[part 22 of 23: package /ComponentTypes]
AUTOSAR XML (schema 4-3-0)
package /ComponentTypes  (continued)
  composition sw component type Geltungsbereich_E3_1_1_UNECE_Gen2  (continued)
    delegate Grundumfang_XIX_Klima.SP_IF_Thermo_Pred_Innen_System_Anf_XIX_Grundumfang_XIX_Klima <-> outer port SP_IF_Thermo_Pred_Innen_System_Anf_XIX_Klima
    delegate Grundumfang_XIX_Klima.SP_IF_Thermo_Pred_P_dyn_In_Efficien1_XIX_Grundumfang_XIX_Klima <-> outer port SP_IF_Thermo_Pred_P_dyn_In_Efficien1_XIX_Klima
    delegate Grundumfang_XIX_Klima.SP_IF_Thermo_Pred_P_dyn_In_Efficien2_XIX_Grundumfang_XIX_Klima <-> outer port SP_IF_Thermo_Pred_P_dyn_In_Efficien2_XIX_Klima
    delegate Grundumfang_XIX_Klima.SP_IF_Thermo_Pred_P_dyn_In_Standard_XIX_Grundumfang_XIX_Klima <-> outer port SP_IF_Thermo_Pred_P_dyn_In_Standard_XIX_Klima
    delegate Grundumfang_XIX_Klima.SP_IF_Thermo_Pred_P_dyn_Innen_XIX_Grundumfang_XIX_Klima <-> outer port SP_IF_Thermo_Pred_P_dyn_Innen_XIX_Klima
    delegate Grundumfang_XIX_Klima.SP_IF_Thermo_Pred_P_stat_In_Efficien1_XIX_Grundumfang_XIX_Klima <-> outer port SP_IF_Thermo_Pred_P_stat_In_Efficien1_XIX_Klima
    delegate Grundumfang_XIX_Klima.SP_IF_Thermo_Pred_P_stat_In_Efficien2_XIX_Grundumfang_XIX_Klima <-> outer port SP_IF_Thermo_Pred_P_stat_In_Efficien2_XIX_Klima
    delegate Grundumfang_XIX_Klima.SP_IF_Thermo_Pred_P_stat_In_Standard_XIX_Grundumfang_XIX_Klima <-> outer port SP_IF_Thermo_Pred_P_stat_In_Standard_XIX_Klima
    delegate Grundumfang_XIX_Klima.SP_IF_Thermo_Pred_P_stat_Innen_XIX_Grundumfang_XIX_Klima <-> outer port SP_IF_Thermo_Pred_P_stat_Innen_XIX_Klima
    delegate Grundumfang_XIX_Klima.SP_IF_Thermo_Pred_T_dyn_In_Efficien1_XIX_Grundumfang_XIX_Klima <-> outer port SP_IF_Thermo_Pred_T_dyn_In_Efficien1_XIX_Klima
    delegate Grundumfang_XIX_Klima.SP_IF_Thermo_Pred_T_dyn_In_Efficien2_XIX_Grundumfang_XIX_Klima <-> outer port SP_IF_Thermo_Pred_T_dyn_In_Efficien2_XIX_Klima
    delegate Grundumfang_XIX_Klima.SP_IF_Thermo_Pred_T_dyn_In_Standard_XIX_Grundumfang_XIX_Klima <-> outer port SP_IF_Thermo_Pred_T_dyn_In_Standard_XIX_Klima
    delegate Grundumfang_XIX_Klima.SP_IF_Thermo_Pred_T_dyn_Innen_XIX_Grundumfang_XIX_Klima <-> outer port SP_IF_Thermo_Pred_T_dyn_Innen_XIX_Klima
    delegate Grundumfang_XIX_Klima.SP_IF_Thermo_Verbrauch_BTL_Ueberlauf_XIX_Grundumfang_XIX_Klima <-> outer port SP_IF_Thermo_Verbrauch_BTL_Ueberlauf_XIX_Klima
    delegate Grundumfang_XIX_Klima.SP_IF_Thermo_Verbrauch_BTL_XIX_Grundumfang_XIX_Klima <-> outer port SP_IF_Thermo_Verbrauch_BTL_XIX_Klima
    delegate Grundumfang_XIX_Klima.SP_IF_Thermo_Verbrauch_Innen_Ueberlauf_XIX_Grundumfang_XIX_Klima <-> outer port SP_IF_Thermo_Verbrauch_Innen_Ueberlauf_XIX_Klima
    delegate Grundumfang_XIX_Klima.SP_IF_Thermo_Verbrauch_Innen_XIX_Grundumfang_XIX_Klima <-> outer port SP_IF_Thermo_Verbrauch_Innen_XIX_Klima
    delegate Grundumfang_XIX_Klima.SP_IF_UH_Jahr_XIX_Grundumfang_XIX_Klima <-> outer port SP_IF_UH_Jahr_XIX_Klima
    delegate Grundumfang_XIX_Klima.SP_IF_UH_Monat_XIX_Grundumfang_XIX_Klima <-> outer port SP_IF_UH_Monat_XIX_Klima
    delegate Grundumfang_XIX_Klima.SP_IF_UH_Tag_XIX_Grundumfang_XIX_Klima <-> outer port SP_IF_UH_Tag_XIX_Klima
    delegate Grundumfang_XIX_Klima.SP_IF_Umluft_XIX_Grundumfang_XIX_Klima <-> outer port SP_IF_Umluft_XIX_Klima
    delegate Grundumfang_XIX_Klima.SP_IF_Verbauposition_LLR_li_XIX_Grundumfang_XIX_Klima <-> outer port SP_IF_Verbauposition_LLR_li_XIX_Klima
    delegate Grundumfang_XIX_Klima.SP_IF_Verbauposition_LLR_re_XIX_Grundumfang_XIX_Klima <-> outer port SP_IF_Verbauposition_LLR_re_XIX_Klima
    delegate Grundumfang_XIX_Klima.SP_IF_ZAS_Kl_15_XIX_Grundumfang_XIX_Klima <-> outer port SP_IF_ZAS_Kl_15_XIX_Klima
    delegate Grundumfang_XIX_Klima.SP_IF_ZAS_Kl_S_XIX_Grundumfang_XIX_Klima <-> outer port SP_IF_ZAS_Kl_S_XIX_Klima
    connect Grundumfang_XIX_Klima.SP_IF_KL_Heizen_Status_XIX_Grundumfang_XIX_Klima -> HVEM_Auto_NL_XIX_Klima.RP_IF_KL_Heizen_Status_XIX_HVEM_Auto_NL_XIX_Klima
    connect Grundumfang_XIX_Klima.SP_IF_KL_Kuehlungs_Status_XIX_Grundumfang_XIX_Klima -> HVEM_Auto_NL_XIX_Klima.RP_IF_KL_Kuehlungs_Status_XIX_HVEM_Auto_NL_XIX_Klima
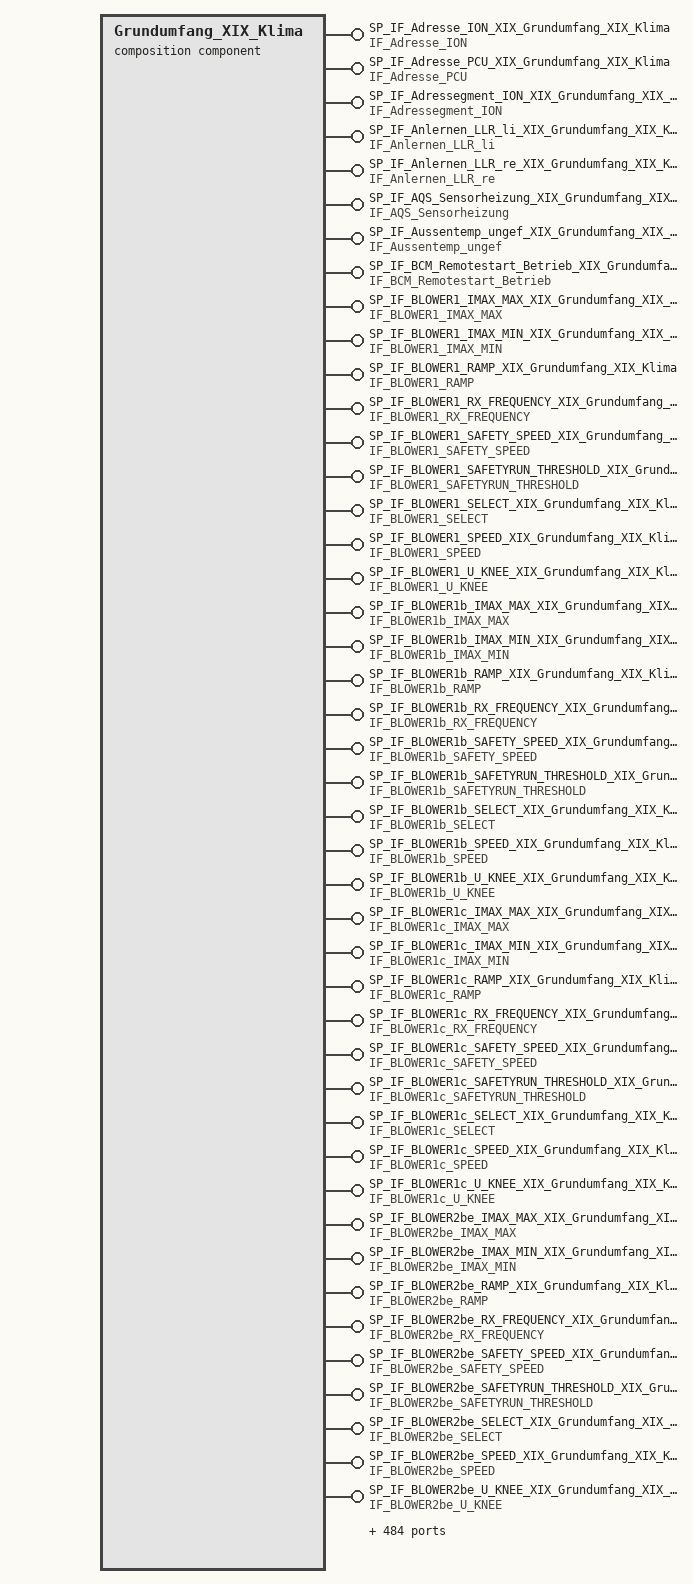
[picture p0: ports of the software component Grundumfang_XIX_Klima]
  composition sw component type Grundumfang_XIX_Klima
    543 x provide port:
      SP_IF_Adresse_ION_XIX_Grundumfang_XIX_Klima: provided-interface=IF_Adresse_ION
      SP_IF_Adresse_PCU_XIX_Grundumfang_XIX_Klima: provided-interface=IF_Adresse_PCU
      SP_IF_Adressegment_ION_XIX_Grundumfang_XIX_Klima: provided-interface=IF_Adressegment_ION
      SP_IF_Anlernen_LLR_li_XIX_Grundumfang_XIX_Klima: provided-interface=IF_Anlernen_LLR_li
      SP_IF_Anlernen_LLR_re_XIX_Grundumfang_XIX_Klima: provided-interface=IF_Anlernen_LLR_re
      SP_IF_AQS_Sensorheizung_XIX_Grundumfang_XIX_Klima: provided-interface=IF_AQS_Sensorheizung
      SP_IF_Aussentemp_ungef_XIX_Grundumfang_XIX_Klima: provided-interface=IF_Aussentemp_ungef
      SP_IF_BCM_Remotestart_Betrieb_XIX_Grundumfang_XIX_Klima: provided-interface=IF_BCM_Remotestart_Betrieb
      SP_IF_BLOWER1_IMAX_MAX_XIX_Grundumfang_XIX_Klima: provided-interface=IF_BLOWER1_IMAX_MAX
      SP_IF_BLOWER1_IMAX_MIN_XIX_Grundumfang_XIX_Klima: provided-interface=IF_BLOWER1_IMAX_MIN
      SP_IF_BLOWER1_RAMP_XIX_Grundumfang_XIX_Klima: provided-interface=IF_BLOWER1_RAMP
      SP_IF_BLOWER1_RX_FREQUENCY_XIX_Grundumfang_XIX_Klima: provided-interface=IF_BLOWER1_RX_FREQUENCY
      SP_IF_BLOWER1_SAFETY_SPEED_XIX_Grundumfang_XIX_Klima: provided-interface=IF_BLOWER1_SAFETY_SPEED
      SP_IF_BLOWER1_SAFETYRUN_THRESHOLD_XIX_Grundumfang_XIX_Klima: provided-interface=IF_BLOWER1_SAFETYRUN_THRESHOLD
      SP_IF_BLOWER1_SELECT_XIX_Grundumfang_XIX_Klima: provided-interface=IF_BLOWER1_SELECT
      SP_IF_BLOWER1_SPEED_XIX_Grundumfang_XIX_Klima: provided-interface=IF_BLOWER1_SPEED
      SP_IF_BLOWER1_U_KNEE_XIX_Grundumfang_XIX_Klima: provided-interface=IF_BLOWER1_U_KNEE
      SP_IF_BLOWER1b_IMAX_MAX_XIX_Grundumfang_XIX_Klima: provided-interface=IF_BLOWER1b_IMAX_MAX
      SP_IF_BLOWER1b_IMAX_MIN_XIX_Grundumfang_XIX_Klima: provided-interface=IF_BLOWER1b_IMAX_MIN
      SP_IF_BLOWER1b_RAMP_XIX_Grundumfang_XIX_Klima: provided-interface=IF_BLOWER1b_RAMP
      SP_IF_BLOWER1b_RX_FREQUENCY_XIX_Grundumfang_XIX_Klima: provided-interface=IF_BLOWER1b_RX_FREQUENCY
      SP_IF_BLOWER1b_SAFETY_SPEED_XIX_Grundumfang_XIX_Klima: provided-interface=IF_BLOWER1b_SAFETY_SPEED
      SP_IF_BLOWER1b_SAFETYRUN_THRESHOLD_XIX_Grundumfang_XIX_Klima: provided-interface=IF_BLOWER1b_SAFETYRUN_THRESHOLD
      SP_IF_BLOWER1b_SELECT_XIX_Grundumfang_XIX_Klima: provided-interface=IF_BLOWER1b_SELECT
      SP_IF_BLOWER1b_SPEED_XIX_Grundumfang_XIX_Klima: provided-interface=IF_BLOWER1b_SPEED
      SP_IF_BLOWER1b_U_KNEE_XIX_Grundumfang_XIX_Klima: provided-interface=IF_BLOWER1b_U_KNEE
      SP_IF_BLOWER1c_IMAX_MAX_XIX_Grundumfang_XIX_Klima: provided-interface=IF_BLOWER1c_IMAX_MAX
      SP_IF_BLOWER1c_IMAX_MIN_XIX_Grundumfang_XIX_Klima: provided-interface=IF_BLOWER1c_IMAX_MIN
      SP_IF_BLOWER1c_RAMP_XIX_Grundumfang_XIX_Klima: provided-interface=IF_BLOWER1c_RAMP
      SP_IF_BLOWER1c_RX_FREQUENCY_XIX_Grundumfang_XIX_Klima: provided-interface=IF_BLOWER1c_RX_FREQUENCY
      SP_IF_BLOWER1c_SAFETY_SPEED_XIX_Grundumfang_XIX_Klima: provided-interface=IF_BLOWER1c_SAFETY_SPEED
      SP_IF_BLOWER1c_SAFETYRUN_THRESHOLD_XIX_Grundumfang_XIX_Klima: provided-interface=IF_BLOWER1c_SAFETYRUN_THRESHOLD
      SP_IF_BLOWER1c_SELECT_XIX_Grundumfang_XIX_Klima: provided-interface=IF_BLOWER1c_SELECT
      SP_IF_BLOWER1c_SPEED_XIX_Grundumfang_XIX_Klima: provided-interface=IF_BLOWER1c_SPEED
      SP_IF_BLOWER1c_U_KNEE_XIX_Grundumfang_XIX_Klima: provided-interface=IF_BLOWER1c_U_KNEE
      SP_IF_BLOWER2be_IMAX_MAX_XIX_Grundumfang_XIX_Klima: provided-interface=IF_BLOWER2be_IMAX_MAX
      SP_IF_BLOWER2be_IMAX_MIN_XIX_Grundumfang_XIX_Klima: provided-interface=IF_BLOWER2be_IMAX_MIN
      SP_IF_BLOWER2be_RAMP_XIX_Grundumfang_XIX_Klima: provided-interface=IF_BLOWER2be_RAMP
      SP_IF_BLOWER2be_RX_FREQUENCY_XIX_Grundumfang_XIX_Klima: provided-interface=IF_BLOWER2be_RX_FREQUENCY
      SP_IF_BLOWER2be_SAFETY_SPEED_XIX_Grundumfang_XIX_Klima: provided-interface=IF_BLOWER2be_SAFETY_SPEED
      SP_IF_BLOWER2be_SAFETYRUN_THRESHOLD_XIX_Grundumfang_XIX_Klima: provided-interface=IF_BLOWER2be_SAFETYRUN_THRESHOLD
      SP_IF_BLOWER2be_SELECT_XIX_Grundumfang_XIX_Klima: provided-interface=IF_BLOWER2be_SELECT
      SP_IF_BLOWER2be_SPEED_XIX_Grundumfang_XIX_Klima: provided-interface=IF_BLOWER2be_SPEED
      SP_IF_BLOWER2be_U_KNEE_XIX_Grundumfang_XIX_Klima: provided-interface=IF_BLOWER2be_U_KNEE
      SP_IF_BLOWER2e_IMAX_MAX_XIX_Grundumfang_XIX_Klima: provided-interface=IF_BLOWER2e_IMAX_MAX
      SP_IF_BLOWER2e_IMAX_MIN_XIX_Grundumfang_XIX_Klima: provided-interface=IF_BLOWER2e_IMAX_MIN
      SP_IF_BLOWER2e_RAMP_XIX_Grundumfang_XIX_Klima: provided-interface=IF_BLOWER2e_RAMP
      SP_IF_BLOWER2e_RX_FREQUENCY_XIX_Grundumfang_XIX_Klima: provided-interface=IF_BLOWER2e_RX_FREQUENCY
      SP_IF_BLOWER2e_SAFETY_SPEED_XIX_Grundumfang_XIX_Klima: provided-interface=IF_BLOWER2e_SAFETY_SPEED
      SP_IF_BLOWER2e_SAFETYRUN_THRESHOLD_XIX_Grundumfang_XIX_Klima: provided-interface=IF_BLOWER2e_SAFETYRUN_THRESHOLD
      SP_IF_BLOWER2e_SELECT_XIX_Grundumfang_XIX_Klima: provided-interface=IF_BLOWER2e_SELECT
      SP_IF_BLOWER2e_SPEED_XIX_Grundumfang_XIX_Klima: provided-interface=IF_BLOWER2e_SPEED
      SP_IF_BLOWER2e_U_KNEE_XIX_Grundumfang_XIX_Klima: provided-interface=IF_BLOWER2e_U_KNEE
      SP_IF_BT_FH_Oeffnung_4Bit_XIX_Grundumfang_XIX_Klima: provided-interface=IF_BT_FH_Oeffnung_4Bit
      SP_IF_DI_KL_58xd_XIX_Grundumfang_XIX_Klima: provided-interface=IF_DI_KL_58xd
      SP_IF_DI_KL_58xs_XIX_Grundumfang_XIX_Klima: provided-interface=IF_DI_KL_58xs
      SP_IF_DS_Kaeltemittel_P_WP_XIX_Grundumfang_XIX_Klima: provided-interface=IF_DS_Kaeltemittel_P_WP
      SP_IF_DS_Kaeltemittel_P_XIX_Grundumfang_XIX_Klima: provided-interface=IF_DS_Kaeltemittel_P
      SP_IF_DS_Status_XIX_Grundumfang_XIX_Klima: provided-interface=IF_DS_Status
      SP_IF_EKK_Active_Discharge_XIX_Grundumfang_XIX_Klima: provided-interface=IF_EKK_Active_Discharge
      SP_IF_EKK_ENB_COMP_XIX_Grundumfang_XIX_Klima: provided-interface=IF_EKK_ENB_COMP
      SP_IF_EKK_HV_ST_XIX_Grundumfang_XIX_Klima: provided-interface=IF_EKK_HV_ST
      SP_IF_EKK_KL_15_Status_XIX_Grundumfang_XIX_Klima: provided-interface=IF_EKK_KL_15_Status
      SP_IF_EKK_REQ_COMP_SPEED_HiRes_XIX_Grundumfang_XIX_Klima: provided-interface=IF_EKK_REQ_COMP_SPEED_HiRes
      SP_IF_EKK_REQ_COMP_SPEED_XIX_Grundumfang_XIX_Klima: provided-interface=IF_EKK_REQ_COMP_SPEED
      SP_IF_EKKe_Error_Mask_Nr_XIX_Grundumfang_XIX_Klima: provided-interface=IF_EKKe_Error_Mask_Nr
      SP_IF_EKKe_Level_REQ_XIX_Grundumfang_XIX_Klima: provided-interface=IF_EKKe_Level_REQ
      SP_IF_EKKe_Q_Mask_XIX_Grundumfang_XIX_Klima: provided-interface=IF_EKKe_Q_Mask
      SP_IF_Empfindlichkeit_AQS_XIX_Grundumfang_XIX_Klima: provided-interface=IF_Empfindlichkeit_AQS
      SP_IF_ESP_v_Signal_8Bit_XIX_Grundumfang_XIX_Klima: provided-interface=IF_ESP_v_Signal_8Bit
      SP_IF_FCM_01_alt_XIX_Grundumfang_XIX_Klima: provided-interface=IF_FCM_01_alt
      SP_IF_FRS_ChannelSelect_XIX_Grundumfang_XIX_Klima: provided-interface=IF_FRS_ChannelSelect
      SP_IF_FRS_IntensityReq_XIX_Grundumfang_XIX_Klima: provided-interface=IF_FRS_IntensityReq
      SP_IF_FRS_Status_Car_XIX_Grundumfang_XIX_Klima: provided-interface=IF_FRS_Status_Car
      SP_IF_FSA_Luftfeuchte_rel_XIX_Grundumfang_XIX_Klima: provided-interface=IF_FSA_Luftfeuchte_rel
      SP_IF_FSA_Taupunkt_PMS_XIX_Grundumfang_XIX_Klima: provided-interface=IF_FSA_Taupunkt_PMS
      SP_IF_FSH_Status_XIX_Grundumfang_XIX_Klima: provided-interface=IF_FSH_Status
      SP_IF_FSH_Taster_XIX_Grundumfang_XIX_Klima: provided-interface=IF_FSH_Taster
      SP_IF_FT_FH_Oeffnung_4Bit_XIX_Grundumfang_XIX_Klima: provided-interface=IF_FT_FH_Oeffnung_4Bit
      SP_IF_Geblaesestufe_XIX_Grundumfang_XIX_Klima: provided-interface=IF_Geblaesestufe
      SP_IF_HBFS_FH_Oeffnung_4Bit_XIX_Grundumfang_XIX_Klima: provided-interface=IF_HBFS_FH_Oeffnung_4Bit
      SP_IF_HFS_FH_Oeffnung_4Bit_XIX_Grundumfang_XIX_Klima: provided-interface=IF_HFS_FH_Oeffnung_4Bit
      SP_IF_HLR_SIH_Freigabe_Fond_XIX_Grundumfang_XIX_Klima: provided-interface=IF_HLR_SIH_Freigabe_Fond
      SP_IF_HSH_Relais_Anf_XIX_Grundumfang_XIX_Klima: provided-interface=IF_HSH_Relais_Anf
      SP_IF_HSH_Taster_XIX_Grundumfang_XIX_Klima: provided-interface=IF_HSH_Taster
      SP_IF_HV_H3be_Geblaesedrehzahl_XIX_Grundumfang_XIX_Klima: provided-interface=IF_HV_H3be_Geblaesedrehzahl
      SP_IF_HV_H3be_Heizer_ein_XIX_Grundumfang_XIX_Klima: provided-interface=IF_HV_H3be_Heizer_ein
      SP_IF_HV_H3be_Heizer_links_soll_XIX_Grundumfang_XIX_Klima: provided-interface=IF_HV_H3be_Heizer_links_soll
      SP_IF_HV_H3be_Heizer_Mitte_soll_XIX_Grundumfang_XIX_Klima: provided-interface=IF_HV_H3be_Heizer_Mitte_soll
      SP_IF_HV_H3be_Heizer_rechts_soll_XIX_Grundumfang_XIX_Klima: provided-interface=IF_HV_H3be_Heizer_rechts_soll
      SP_IF_HV_H3be_Heizgaskuehler_XIX_Grundumfang_XIX_Klima: provided-interface=IF_HV_H3be_Heizgaskuehler
      SP_IF_HV_H3be_Heizsystem_XIX_Grundumfang_XIX_Klima: provided-interface=IF_HV_H3be_Heizsystem
      SP_IF_HV_H3be_PTC_Zonenanzahl_XIX_Grundumfang_XIX_Klima: provided-interface=IF_HV_H3be_PTC_Zonenanzahl
      SP_IF_HV_H3be_Tempklappenwinkel_li_XIX_Grundumfang_XIX_Klima: provided-interface=IF_HV_H3be_Tempklappenwinkel_li
      SP_IF_HV_H3be_Tempklappenwinkel_mi_XIX_Grundumfang_XIX_Klima: provided-interface=IF_HV_H3be_Tempklappenwinkel_mi
      SP_IF_HV_H3be_Tempklappenwinkel_re_XIX_Grundumfang_XIX_Klima: provided-interface=IF_HV_H3be_Tempklappenwinkel_re
      SP_IF_HV_H3be_Verdampfertemp_Delta_XIX_Grundumfang_XIX_Klima: provided-interface=IF_HV_H3be_Verdampfertemp_Delta
      SP_IF_HV_H3be_Verdampfertemp_min_XIX_Grundumfang_XIX_Klima: provided-interface=IF_HV_H3be_Verdampfertemp_min
      SP_IF_HV_H3e_Geblaesedrehzahl_XIX_Grundumfang_XIX_Klima: provided-interface=IF_HV_H3e_Geblaesedrehzahl
      SP_IF_HV_H3e_Heizer_ein_XIX_Grundumfang_XIX_Klima: provided-interface=IF_HV_H3e_Heizer_ein
      SP_IF_HV_H3e_Heizer_links_soll_XIX_Grundumfang_XIX_Klima: provided-interface=IF_HV_H3e_Heizer_links_soll
      SP_IF_HV_H3e_Heizer_Mitte_soll_XIX_Grundumfang_XIX_Klima: provided-interface=IF_HV_H3e_Heizer_Mitte_soll
      SP_IF_HV_H3e_Heizer_rechts_soll_XIX_Grundumfang_XIX_Klima: provided-interface=IF_HV_H3e_Heizer_rechts_soll
      SP_IF_HV_H3e_Heizgaskuehler_XIX_Grundumfang_XIX_Klima: provided-interface=IF_HV_H3e_Heizgaskuehler
      SP_IF_HV_H3e_Heizsystem_XIX_Grundumfang_XIX_Klima: provided-interface=IF_HV_H3e_Heizsystem
      SP_IF_HV_H3e_PTC_Zonenanzahl_XIX_Grundumfang_XIX_Klima: provided-interface=IF_HV_H3e_PTC_Zonenanzahl
      SP_IF_HV_H3e_Tempklappenwinkel_li_XIX_Grundumfang_XIX_Klima: provided-interface=IF_HV_H3e_Tempklappenwinkel_li
      SP_IF_HV_H3e_Tempklappenwinkel_mi_XIX_Grundumfang_XIX_Klima: provided-interface=IF_HV_H3e_Tempklappenwinkel_mi
      SP_IF_HV_H3e_Tempklappenwinkel_re_XIX_Grundumfang_XIX_Klima: provided-interface=IF_HV_H3e_Tempklappenwinkel_re
      SP_IF_HV_H3e_Verdampfertemp_Delta_XIX_Grundumfang_XIX_Klima: provided-interface=IF_HV_H3e_Verdampfertemp_Delta
      SP_IF_HV_H3e_Verdampfertemp_min_XIX_Grundumfang_XIX_Klima: provided-interface=IF_HV_H3e_Verdampfertemp_min
      SP_IF_ICO2_Luftdruck_2_XIX_Grundumfang_XIX_Klima: provided-interface=IF_ICO2_Luftdruck_2
      SP_IF_ICO2_Messvorgabe_XIX_Grundumfang_XIX_Klima: provided-interface=IF_ICO2_Messvorgabe
      SP_IF_ICO2_Messzyklus1_XIX_Grundumfang_XIX_Klima: provided-interface=IF_ICO2_Messzyklus1
      SP_IF_ICO2_Messzyklus2_XIX_Grundumfang_XIX_Klima: provided-interface=IF_ICO2_Messzyklus2
      SP_IF_ICO2_Status_Kabine_XIX_Grundumfang_XIX_Klima: provided-interface=IF_ICO2_Status_Kabine
      SP_IF_ICO2b_Luftdruck_2_XIX_Grundumfang_XIX_Klima: provided-interface=IF_ICO2b_Luftdruck_2
      SP_IF_ICO2b_Messvorgabe_XIX_Grundumfang_XIX_Klima: provided-interface=IF_ICO2b_Messvorgabe
      SP_IF_ICO2b_Messzyklus1_XIX_Grundumfang_XIX_Klima: provided-interface=IF_ICO2b_Messzyklus1
      SP_IF_ICO2b_Messzyklus2_XIX_Grundumfang_XIX_Klima: provided-interface=IF_ICO2b_Messzyklus2
      SP_IF_ICO2b_Status_Kabine_XIX_Grundumfang_XIX_Klima: provided-interface=IF_ICO2b_Status_Kabine
      SP_IF_ION_0e_Dummy_XIX_Grundumfang_XIX_Klima: provided-interface=IF_ION_0e_Dummy
      SP_IF_ISOALLReqB{0..7}_XIX_Grundumfang_XIX_Klima: provided-interface=IF_ISOALLReqB{0..7}
      SP_IF_KBT_CODE_VEHICLE_XIX_Grundumfang_XIX_Klima: provided-interface=IF_KBT_CODE_VEHICLE
      SP_IF_KBT_Defrost_aktiv_XIX_Grundumfang_XIX_Klima: provided-interface=IF_KBT_Defrost_aktiv
      SP_IF_KBT_RAMP_XIX_Grundumfang_XIX_Klima: provided-interface=IF_KBT_RAMP
      SP_IF_KBT_RX_FREQUENCY_XIX_Grundumfang_XIX_Klima: provided-interface=IF_KBT_RX_FREQUENCY
      SP_IF_KBT_SAFETY_SPEED_XIX_Grundumfang_XIX_Klima: provided-interface=IF_KBT_SAFETY_SPEED
      SP_IF_KBT_SPEED_XIX_Grundumfang_XIX_Klima: provided-interface=IF_KBT_SPEED
      SP_IF_KL_AC_Schalter_XIX_Grundumfang_XIX_Klima: provided-interface=IF_KL_AC_Schalter
      SP_IF_KL_ActiveDischarge_XIX_Grundumfang_XIX_Klima: provided-interface=IF_KL_ActiveDischarge
      SP_IF_KL_AirCleaner_aktiv_XIX_Grundumfang_XIX_Klima: provided-interface=IF_KL_AirCleaner_aktiv
      SP_IF_KL_Ak_Verd_hi_li_XIX_Grundumfang_XIX_Klima: provided-interface=IF_KL_Ak_Verd_hi_li
      SP_IF_KL_Ak_Verd_hi_re_XIX_Grundumfang_XIX_Klima: provided-interface=IF_KL_Ak_Verd_hi_re
      SP_IF_KL_Ak_Verd_hinten_XIX_Grundumfang_XIX_Klima: provided-interface=IF_KL_Ak_Verd_hinten
      SP_IF_KL_Ak_Verd_links_XIX_Grundumfang_XIX_Klima: provided-interface=IF_KL_Ak_Verd_links
      SP_IF_KL_Ak_Verd_rechts_XIX_Grundumfang_XIX_Klima: provided-interface=IF_KL_Ak_Verd_rechts
      SP_IF_KL_Ak_Verd_vo_li_XIX_Grundumfang_XIX_Klima: provided-interface=IF_KL_Ak_Verd_vo_li
      SP_IF_KL_Ak_Verd_vo_re_XIX_Grundumfang_XIX_Klima: provided-interface=IF_KL_Ak_Verd_vo_re
      SP_IF_KL_Ak_Verd_vorne_XIX_Grundumfang_XIX_Klima: provided-interface=IF_KL_Ak_Verd_vorne
      SP_IF_KL_AL_HL_Anf_XIX_Grundumfang_XIX_Klima: provided-interface=IF_KL_AL_HL_Anf
      SP_IF_KL_AL_HR_Anf_XIX_Grundumfang_XIX_Klima: provided-interface=IF_KL_AL_HR_Anf
      SP_IF_KL_AL_VL_Anf_XIX_Grundumfang_XIX_Klima: provided-interface=IF_KL_AL_VL_Anf
      SP_IF_KL_AL_VR_Anf_XIX_Grundumfang_XIX_Klima: provided-interface=IF_KL_AL_VR_Anf
      SP_IF_KL_Anf_AussenspiegelHzg_XIX_Grundumfang_XIX_Klima: provided-interface=IF_KL_Anf_AussenspiegelHzg
      SP_IF_KL_Anf_KL_XIX_Grundumfang_XIX_Klima: provided-interface=IF_KL_Anf_KL
      SP_IF_KL_Anf_KV_XIX_Grundumfang_XIX_Klima: provided-interface=IF_KL_Anf_KV
      SP_IF_KL_Anf_rLM_XIX_Grundumfang_XIX_Klima: provided-interface=IF_KL_Anf_rLM
      SP_IF_KL_Anz_auto_hl_XIX_Grundumfang_XIX_Klima: provided-interface=IF_KL_Anz_auto_hl
      SP_IF_KL_Anz_Geblaese_hl_XIX_Grundumfang_XIX_Klima: provided-interface=IF_KL_Anz_Geblaese_hl
      SP_IF_KL_Anz_mitte_hl_XIX_Grundumfang_XIX_Klima: provided-interface=IF_KL_Anz_mitte_hl
      SP_IF_KL_Anz_oben_hl_XIX_Grundumfang_XIX_Klima: provided-interface=IF_KL_Anz_oben_hl
      SP_IF_KL_Anz_seite_defog_hl_XIX_Grundumfang_XIX_Klima: provided-interface=IF_KL_Anz_seite_defog_hl
      SP_IF_KL_Anz_seite_hl_XIX_Grundumfang_XIX_Klima: provided-interface=IF_KL_Anz_seite_hl
      SP_IF_KL_Anz_Temp_Einheit_XIX_Grundumfang_XIX_Klima: provided-interface=IF_KL_Anz_Temp_Einheit
      SP_IF_KL_Anz_Temp_hl_XIX_Grundumfang_XIX_Klima: provided-interface=IF_KL_Anz_Temp_hl
      SP_IF_KL_Anz_Temp_hr_XIX_Grundumfang_XIX_Klima: provided-interface=IF_KL_Anz_Temp_hr
      SP_IF_KL_Anz_unten_hl_XIX_Grundumfang_XIX_Klima: provided-interface=IF_KL_Anz_unten_hl
      SP_IF_KL_AQI_Innenraum_XIX_Grundumfang_XIX_Klima: provided-interface=IF_KL_AQI_Innenraum
      SP_IF_KL_Ausstattung_Klima_XIX_Grundumfang_XIX_Klima: provided-interface=IF_KL_Ausstattung_Klima
      SP_IF_KL_Batterieheizen_Freigabe_XIX_Grundumfang_XIX_Klima: provided-interface=IF_KL_Batterieheizen_Freigabe
      SP_IF_KL_BattKond_WaPu_DZMax_XIX_Grundumfang_XIX_Klima: provided-interface=IF_KL_BattKond_WaPu_DZMax
      SP_IF_KL_BCmE_Livetip_Freigabe_XIX_Grundumfang_XIX_Klima: provided-interface=IF_KL_BCmE_Livetip_Freigabe
      SP_IF_KL_Beschlagsgefahr_XIX_Grundumfang_XIX_Klima: provided-interface=IF_KL_Beschlagsgefahr
      SP_IF_KL_Charisma_FahrPr_XIX_Grundumfang_XIX_Klima: provided-interface=IF_KL_Charisma_FahrPr
      SP_IF_KL_Charisma_Status_XIX_Grundumfang_XIX_Klima: provided-interface=IF_KL_Charisma_Status
      SP_IF_KL_Defrost_LED_XIX_Grundumfang_XIX_Klima: provided-interface=IF_KL_Defrost_LED
      SP_IF_KL_Drehz_Anh_XIX_Grundumfang_XIX_Klima: provided-interface=IF_KL_Drehz_Anh
      SP_IF_KL_Einheiten_XIX_Grundumfang_XIX_Klima: provided-interface=IF_KL_Einheiten
      SP_IF_KL_EKK_Strom_XIX_Grundumfang_XIX_Klima: provided-interface=IF_KL_EKK_Strom
      SP_IF_KL_el_Zuheizer_Stufe_XIX_Grundumfang_XIX_Klima: provided-interface=IF_KL_el_Zuheizer_Stufe
      SP_IF_KL_Enteisung_Anf_XIX_Grundumfang_XIX_Klima: provided-interface=IF_KL_Enteisung_Anf
      SP_IF_KL_ErwVK_Anf_XIX_Grundumfang_XIX_Klima: provided-interface=IF_KL_ErwVK_Anf
      SP_IF_KL_ErwVK_Beifahrerzone_XIX_Grundumfang_XIX_Klima: provided-interface=IF_KL_ErwVK_Beifahrerzone
      SP_IF_KL_ErwVK_Fahrerzone_XIX_Grundumfang_XIX_Klima: provided-interface=IF_KL_ErwVK_Fahrerzone
      SP_IF_KL_ErwVK_Heckzone_links_XIX_Grundumfang_XIX_Klima: provided-interface=IF_KL_ErwVK_Heckzone_links
      SP_IF_Kl_ErwVK_Heckzone_rechts_XIX_Grundumfang_XIX_Klima: provided-interface=IF_Kl_ErwVK_Heckzone_rechts
      SP_IF_KL_ErwVK_Scheibenheizung_XIX_Grundumfang_XIX_Klima: provided-interface=IF_KL_ErwVK_Scheibenheizung
      SP_IF_KL_ErwVK_Status_XIX_Grundumfang_XIX_Klima: provided-interface=IF_KL_ErwVK_Status
      SP_IF_KL_eTM_SollVolumenstrom_XIX_Grundumfang_XIX_Klima: provided-interface=IF_KL_eTM_SollVolumenstrom
      SP_IF_KL_Fehler_HV_EKK_XIX_Grundumfang_XIX_Klima: provided-interface=IF_KL_Fehler_HV_EKK
      SP_IF_KL_Fehler_HV_Heizer_XIX_Grundumfang_XIX_Klima: provided-interface=IF_KL_Fehler_HV_Heizer
      SP_IF_KL_Fehler_NTKreis_XIX_Grundumfang_XIX_Klima: provided-interface=IF_KL_Fehler_NTKreis
      SP_IF_KL_Fondbedienung_aktiv_XIX_Grundumfang_XIX_Klima: provided-interface=IF_KL_Fondbedienung_aktiv
      SP_IF_KL_Freilauf_Info_XIX_Grundumfang_XIX_Klima: provided-interface=IF_KL_Freilauf_Info
      SP_IF_KL_FSH_Automatikbetrieb_XIX_Grundumfang_XIX_Klima: provided-interface=IF_KL_FSH_Automatikbetrieb
      SP_IF_KL_FSH_LED_XIX_Grundumfang_XIX_Klima: provided-interface=IF_KL_FSH_LED
      SP_IF_KL_FSH_Soll_XIX_Grundumfang_XIX_Klima: provided-interface=IF_KL_FSH_Soll
      SP_IF_KL_Geblaese_Fond_Status_XIX_Grundumfang_XIX_Klima: provided-interface=IF_KL_Geblaese_Fond_Status
      SP_IF_KL_Geblaese_Status_XIX_Grundumfang_XIX_Klima: provided-interface=IF_KL_Geblaese_Status
      SP_IF_KL_Geblspng_Fond_Soll_XIX_Grundumfang_XIX_Klima: provided-interface=IF_KL_Geblspng_Fond_Soll
      SP_IF_KL_Geblspng_Soll_XIX_Grundumfang_XIX_Klima: provided-interface=IF_KL_Geblspng_Soll
      SP_IF_KL_HBT_Geblaesestufe_anzeigen_XIX_Grundumfang_XIX_Klima: provided-interface=IF_KL_HBT_Geblaesestufe_anzeigen
      SP_IF_KL_HBT_Verbausituation_XIX_Grundumfang_XIX_Klima: provided-interface=IF_KL_HBT_Verbausituation
      SP_IF_KL_Heizbedarf_Anf_XIX_Grundumfang_XIX_Klima: provided-interface=IF_KL_Heizbedarf_Anf
      SP_IF_KL_Heizbedarf_XIX_Grundumfang_XIX_Klima: provided-interface=IF_KL_Heizbedarf
      SP_IF_KL_Heizen_Status_XIX_Grundumfang_XIX_Klima: provided-interface=IF_KL_Heizen_Status
      SP_IF_KL_Heizkreisventilstellung_XIX_Grundumfang_XIX_Klima: provided-interface=IF_KL_Heizkreisventilstellung
      SP_IF_KL_Heizstufe_LSH_XIX_Grundumfang_XIX_Klima: provided-interface=IF_KL_Heizstufe_LSH
      SP_IF_KL_Hinweis_Kuehlmodus_XIX_Grundumfang_XIX_Klima: provided-interface=IF_KL_Hinweis_Kuehlmodus
      SP_IF_KL_HSH_LED_XIX_Grundumfang_XIX_Klima: provided-interface=IF_KL_HSH_LED
      SP_IF_KL_HSH_Soll_XIX_Grundumfang_XIX_Klima: provided-interface=IF_KL_HSH_Soll
      SP_IF_KL_HUP_aktiv_XIX_Grundumfang_XIX_Klima: provided-interface=IF_KL_HUP_aktiv
      SP_IF_KL_HV_Energie_Anf_XIX_Grundumfang_XIX_Klima: provided-interface=IF_KL_HV_Energie_Anf
      SP_IF_KL_HV_H6_aktive_Entladung_XIX_Grundumfang_XIX_Klima: provided-interface=IF_KL_HV_H6_aktive_Entladung
      SP_IF_KL_HV_H6_Durchflussrichtung_XIX_Grundumfang_XIX_Klima: provided-interface=IF_KL_HV_H6_Durchflussrichtung
      SP_IF_KL_HV_H6_ein_XIX_Grundumfang_XIX_Klima: provided-interface=IF_KL_HV_H6_ein
      SP_IF_KL_HV_H6_soll_XIX_Grundumfang_XIX_Klima: provided-interface=IF_KL_HV_H6_soll
      SP_IF_KL_HV_Hb_ein_XIX_Grundumfang_XIX_Klima: provided-interface=IF_KL_HV_Hb_ein
      SP_IF_KL_HV_Hb_soll_XIX_Grundumfang_XIX_Klima: provided-interface=IF_KL_HV_Hb_soll
      SP_IF_KL_HV_Heizer_Strom_XIX_Grundumfang_XIX_Klima: provided-interface=IF_KL_HV_Heizer_Strom
      SP_IF_KL_HV_PTC_ein_XIX_Grundumfang_XIX_Klima: provided-interface=IF_KL_HV_PTC_ein
      SP_IF_KL_HV_PTC_soll_XIX_Grundumfang_XIX_Klima: provided-interface=IF_KL_HV_PTC_soll
      SP_IF_KL_HVH_1_VerbautStatus_XIX_Grundumfang_XIX_Klima: provided-interface=IF_KL_HVH_1_VerbautStatus
      SP_IF_KL_HVH_2_Status_Spgfreiheit_XIX_Grundumfang_XIX_Klima: provided-interface=IF_KL_HVH_2_Status_Spgfreiheit
      SP_IF_KL_HVH_2_VerbautStatus_XIX_Grundumfang_XIX_Klima: provided-interface=IF_KL_HVH_2_VerbautStatus
      SP_IF_KL_HVH_3_VerbautStatus_XIX_Grundumfang_XIX_Klima: provided-interface=IF_KL_HVH_3_VerbautStatus
      SP_IF_KL_HVHeizer2_ein_XIX_Grundumfang_XIX_Klima: provided-interface=IF_KL_HVHeizer2_ein
      SP_IF_KL_HVHeizer2_soll_XIX_Grundumfang_XIX_Klima: provided-interface=IF_KL_HVHeizer2_soll
      SP_IF_KL_HWT_Sollvolumenstrom_XIX_Grundumfang_XIX_Klima: provided-interface=IF_KL_HWT_Sollvolumenstrom
      SP_IF_KL_I_Geblaese_Fond_XIX_Grundumfang_XIX_Klima: provided-interface=IF_KL_I_Geblaese_Fond
      SP_IF_KL_I_Geblaese_XIX_Grundumfang_XIX_Klima: provided-interface=IF_KL_I_Geblaese
      SP_IF_KL_Innen_Temp_XIX_Grundumfang_XIX_Klima: provided-interface=IF_KL_Innen_Temp
      SP_IF_KL_Innentemp_KBT_Sensor_XIX_Grundumfang_XIX_Klima: provided-interface=IF_KL_Innentemp_KBT_Sensor
      SP_IF_KL_Ionisator_XIX_Grundumfang_XIX_Klima: provided-interface=IF_KL_Ionisator
      SP_IF_KL_IstLeistung_XIX_Grundumfang_XIX_Klima: provided-interface=IF_KL_IstLeistung
      SP_IF_KL_K_Status_XIX_Grundumfang_XIX_Klima: provided-interface=IF_KL_K_Status
      SP_IF_KL_KBF_Sync_XIX_Grundumfang_XIX_Klima: provided-interface=IF_KL_KBF_Sync
      SP_IF_KL_KD_Fehler_XIX_Grundumfang_XIX_Klima: provided-interface=IF_KL_KD_Fehler
      SP_IF_KL_Kennlinie_XIX_Grundumfang_XIX_Klima: provided-interface=IF_KL_Kennlinie
      SP_IF_KL_Klappe_Status_XIX_Grundumfang_XIX_Klima: provided-interface=IF_KL_Klappe_Status
      SP_IF_KL_KLE_Fehler_Anf_XIX_Grundumfang_XIX_Klima: provided-interface=IF_KL_KLE_Fehler_Anf
      SP_IF_KL_KLh_aus_XIX_Grundumfang_XIX_Klima: provided-interface=IF_KL_KLh_aus
      SP_IF_KL_KLh_LastMode_XIX_Grundumfang_XIX_Klima: provided-interface=IF_KL_KLh_LastMode
      SP_IF_KL_KLh_lock_XIX_Grundumfang_XIX_Klima: provided-interface=IF_KL_KLh_lock
      SP_IF_Kl_Klima_Aktiv_XIX_Grundumfang_XIX_Klima: provided-interface=IF_Kl_Klima_Aktiv
      SP_IF_KL_Klimastandzeit_XIX_Grundumfang_XIX_Klima: provided-interface=IF_KL_Klimastandzeit
      SP_IF_KL_KM_ASV_01_Status_XIX_Grundumfang_XIX_Klima: provided-interface=IF_KL_KM_ASV_01_Status
      SP_IF_KL_KM_ASV_02_Status_XIX_Grundumfang_XIX_Klima: provided-interface=IF_KL_KM_ASV_02_Status
      SP_IF_KL_Komp_Moment_alt_XIX_Grundumfang_XIX_Klima: provided-interface=IF_KL_Komp_Moment_alt
      SP_IF_KL_Kompressorstrom_soll_XIX_Grundumfang_XIX_Klima: provided-interface=IF_KL_Kompressorstrom_soll
      SP_IF_KL_Kuehlungs_Status_XIX_Grundumfang_XIX_Klima: provided-interface=IF_KL_Kuehlungs_Status
      SP_IF_KL_Kundenwunsch_Kuehlen_XIX_Grundumfang_XIX_Klima: provided-interface=IF_KL_Kundenwunsch_Kuehlen
      SP_IF_KL_Last_Kompr_XIX_Grundumfang_XIX_Klima: provided-interface=IF_KL_Last_Kompr
      SP_IF_KL_Leistung_BattHeizung_XIX_Grundumfang_XIX_Klima: provided-interface=IF_KL_Leistung_BattHeizung
      SP_IF_KL_Leistung_Klima_Anf_XIX_Grundumfang_XIX_Klima: provided-interface=IF_KL_Leistung_Klima_Anf
      SP_IF_KL_LRH_FoD_Status_XIX_Grundumfang_XIX_Klima: provided-interface=IF_KL_LRH_FoD_Status
      SP_IF_KL_LRH_PWM_XIX_Grundumfang_XIX_Klima: provided-interface=IF_KL_LRH_PWM
      SP_IF_KL_LRH_Soll_XIX_Grundumfang_XIX_Klima: provided-interface=IF_KL_LRH_Soll
      SP_IF_KL_LRH_Stufe_XIX_Grundumfang_XIX_Klima: provided-interface=IF_KL_LRH_Stufe
      SP_IF_KL_LRH_Taster_XIX_Grundumfang_XIX_Klima: provided-interface=IF_KL_LRH_Taster
      SP_IF_KL_LSH_Ansteuerung_XIX_Grundumfang_XIX_Klima: provided-interface=IF_KL_LSH_Ansteuerung
      SP_IF_KL_LSH_Betriebsdauer_XIX_Grundumfang_XIX_Klima: provided-interface=IF_KL_LSH_Betriebsdauer
      SP_IF_KL_LSH_DBetr_Bestaet_XIX_Grundumfang_XIX_Klima: provided-interface=IF_KL_LSH_DBetr_Bestaet
      SP_IF_KL_LSH_DBetr_Ein_XIX_Grundumfang_XIX_Klima: provided-interface=IF_KL_LSH_DBetr_Ein
      SP_IF_KL_Magnetventil_XIX_Grundumfang_XIX_Klima: provided-interface=IF_KL_Magnetventil
      SP_IF_Kl_Meldung_Status2_XIX_Grundumfang_XIX_Klima: provided-interface=IF_Kl_Meldung_Status2
      SP_IF_KL_Meldung_Status_XIX_Grundumfang_XIX_Klima: provided-interface=IF_KL_Meldung_Status
      SP_IF_KL_nachtr_Stopp_Anf_XIX_Grundumfang_XIX_Klima: provided-interface=IF_KL_nachtr_Stopp_Anf
      SP_IF_KL_OBD_Status_Auth_XIX_Grundumfang_XIX_Klima: provided-interface=IF_KL_OBD_Status_Auth
      SP_IF_KL_OBD_Status_XIX_Grundumfang_XIX_Klima: provided-interface=IF_KL_OBD_Status
      SP_IF_KL_PTC_ein_XIX_Grundumfang_XIX_Klima: provided-interface=IF_KL_PTC_ein
      SP_IF_KL_PTC_Rampe_XIX_Grundumfang_XIX_Klima: provided-interface=IF_KL_PTC_Rampe
      SP_IF_KL_PTC_soll_XIX_Grundumfang_XIX_Klima: provided-interface=IF_KL_PTC_soll
      SP_IF_KL_PTC_Verbauinfo_XIX_Grundumfang_XIX_Klima: provided-interface=IF_KL_PTC_Verbauinfo
      SP_IF_KL_Pumpe_02_Soll_XIX_Grundumfang_XIX_Klima: provided-interface=IF_KL_Pumpe_02_Soll
      SP_IF_KL_Reheat_Innenraum_XIX_Grundumfang_XIX_Klima: provided-interface=IF_KL_Reheat_Innenraum
      SP_IF_KL_Restwaerme_aktiv_XIX_Grundumfang_XIX_Klima: provided-interface=IF_KL_Restwaerme_aktiv
      SP_IF_KL_Scheibe_Typ_XIX_Grundumfang_XIX_Klima: provided-interface=IF_KL_Scheibe_Typ
      SP_IF_KL_SDA_AQS_COBereich_XIX_Grundumfang_XIX_Klima: provided-interface=IF_KL_SDA_AQS_COBereich
      SP_IF_KL_SDA_AQS_COStatus_XIX_Grundumfang_XIX_Klima: provided-interface=IF_KL_SDA_AQS_COStatus
      SP_IF_KL_SDA_AQS_NoxBereich_XIX_Grundumfang_XIX_Klima: provided-interface=IF_KL_SDA_AQS_NoxBereich
      SP_IF_KL_SDA_AQS_NoxStatus_XIX_Grundumfang_XIX_Klima: provided-interface=IF_KL_SDA_AQS_NoxStatus
      SP_IF_KL_SDA_AQS_Traffic_XIX_Grundumfang_XIX_Klima: provided-interface=IF_KL_SDA_AQS_Traffic
      SP_IF_KL_SDA_AQS_VOZBereich_XIX_Grundumfang_XIX_Klima: provided-interface=IF_KL_SDA_AQS_VOZBereich
      SP_IF_KL_SDA_AQS_VOZStatus_XIX_Grundumfang_XIX_Klima: provided-interface=IF_KL_SDA_AQS_VOZStatus
      SP_IF_KL_SDA_Klima_Automatik_XIX_Grundumfang_XIX_Klima: provided-interface=IF_KL_SDA_Klima_Automatik
      SP_IF_KL_SDA_Luft_Feinstaub_XIX_Grundumfang_XIX_Klima: provided-interface=IF_KL_SDA_Luft_Feinstaub
      SP_IF_KL_SDA_Luft_Qualitaet_XIX_Grundumfang_XIX_Klima: provided-interface=IF_KL_SDA_Luft_Qualitaet
      SP_IF_KL_SDA_Luftverteilung_Person_XIX_Grundumfang_XIX_Klima: provided-interface=IF_KL_SDA_Luftverteilung_Person
      SP_IF_KL_SDA_Luftverteilung_Scheibe_XIX_Grundumfang_XIX_Klima: provided-interface=IF_KL_SDA_Luftverteilung_Scheibe
      SP_IF_KL_SDA_Luftverteilung_Unten_XIX_Grundumfang_XIX_Klima: provided-interface=IF_KL_SDA_Luftverteilung_Unten
      SP_IF_KL_SDA_Menutaste_XIX_Grundumfang_XIX_Klima: provided-interface=IF_KL_SDA_Menutaste
      SP_IF_KL_SDA_Sitzheizung_VL_XIX_Grundumfang_XIX_Klima: provided-interface=IF_KL_SDA_Sitzheizung_VL
      SP_IF_KL_SDA_Sitzheizung_VR_XIX_Grundumfang_XIX_Klima: provided-interface=IF_KL_SDA_Sitzheizung_VR
      SP_IF_KL_SDA_Sitzlueftung_VL_XIX_Grundumfang_XIX_Klima: provided-interface=IF_KL_SDA_Sitzlueftung_VL
      SP_IF_KL_SDA_Sitzlueftung_VR_XIX_Grundumfang_XIX_Klima: provided-interface=IF_KL_SDA_Sitzlueftung_VR
      SP_IF_KL_SDA_Sonderfkt_AirCare_XIX_Grundumfang_XIX_Klima: provided-interface=IF_KL_SDA_Sonderfkt_AirCare
      SP_IF_KL_SDA_Sonderfkt_HSH_XIX_Grundumfang_XIX_Klima: provided-interface=IF_KL_SDA_Sonderfkt_HSH
      SP_IF_KL_SDA_Sonderfkt_MaxAC_XIX_Grundumfang_XIX_Klima: provided-interface=IF_KL_SDA_Sonderfkt_MaxAC
      SP_IF_KL_SDA_Sonderfkt_MaxDefrost_XIX_Grundumfang_XIX_Klima: provided-interface=IF_KL_SDA_Sonderfkt_MaxDefrost
      SP_IF_KL_SDA_Sonderfunktionen_Sprache_XIX_Grundumfang_XIX_Klima: provided-interface=IF_KL_SDA_Sonderfunktionen_Sprache
      SP_IF_KL_SDA_Temp_Kundenwunsch_2_XIX_Grundumfang_XIX_Klima: provided-interface=IF_KL_SDA_Temp_Kundenwunsch_2
      SP_IF_KL_SDA_Temp_Kundenwunsch_3_XIX_Grundumfang_XIX_Klima: provided-interface=IF_KL_SDA_Temp_Kundenwunsch_3
      SP_IF_KL_SH_Soll_hl_XIX_Grundumfang_XIX_Klima: provided-interface=IF_KL_SH_Soll_hl
      SP_IF_KL_SH_Soll_hr_XIX_Grundumfang_XIX_Klima: provided-interface=IF_KL_SH_Soll_hr
      SP_IF_KL_SIH_Anforderung_hl_XIX_Grundumfang_XIX_Klima: provided-interface=IF_KL_SIH_Anforderung_hl
      SP_IF_KL_SIH_Anforderung_hr_XIX_Grundumfang_XIX_Klima: provided-interface=IF_KL_SIH_Anforderung_hr
      SP_IF_KL_SIH_hl_Leistung_XIX_Grundumfang_XIX_Klima: provided-interface=IF_KL_SIH_hl_Leistung
      SP_IF_KL_SIH_hl_Temp_aus_XIX_Grundumfang_XIX_Klima: provided-interface=IF_KL_SIH_hl_Temp_aus
      SP_IF_KL_SIH_hl_Temp_ein_XIX_Grundumfang_XIX_Klima: provided-interface=IF_KL_SIH_hl_Temp_ein
      SP_IF_KL_SIH_hl_Vorgabe_XIX_Grundumfang_XIX_Klima: provided-interface=IF_KL_SIH_hl_Vorgabe
      SP_IF_KL_SIH_hr_Leistung_XIX_Grundumfang_XIX_Klima: provided-interface=IF_KL_SIH_hr_Leistung
      SP_IF_KL_SIH_hr_Temp_aus_XIX_Grundumfang_XIX_Klima: provided-interface=IF_KL_SIH_hr_Temp_aus
      SP_IF_KL_SIH_hr_Temp_ein_XIX_Grundumfang_XIX_Klima: provided-interface=IF_KL_SIH_hr_Temp_ein
      SP_IF_KL_SIH_hr_Vorgabe_XIX_Grundumfang_XIX_Klima: provided-interface=IF_KL_SIH_hr_Vorgabe
      SP_IF_KL_SIH_LEL_Verteilung_VL_XIX_Grundumfang_XIX_Klima: provided-interface=IF_KL_SIH_LEL_Verteilung_VL
      SP_IF_KL_SIH_LEL_Verteilung_VR_XIX_Grundumfang_XIX_Klima: provided-interface=IF_KL_SIH_LEL_Verteilung_VR
      SP_IF_KL_SIH_Soll_li_XIX_Grundumfang_XIX_Klima: provided-interface=IF_KL_SIH_Soll_li
      SP_IF_KL_SIH_Soll_re_XIX_Grundumfang_XIX_Klima: provided-interface=IF_KL_SIH_Soll_re
      SP_IF_KL_SIL_Soll_li_XIX_Grundumfang_XIX_Klima: provided-interface=IF_KL_SIL_Soll_li
      SP_IF_KL_SIL_Soll_re_XIX_Grundumfang_XIX_Klima: provided-interface=IF_KL_SIL_Soll_re
      SP_IF_KL_Sitzkennlinie_Heck_XIX_Grundumfang_XIX_Klima: provided-interface=IF_KL_Sitzkennlinie_Heck
      SP_IF_KL_SL_Soll_hl_XIX_Grundumfang_XIX_Klima: provided-interface=IF_KL_SL_Soll_hl
      SP_IF_KL_SL_Soll_hr_XIX_Grundumfang_XIX_Klima: provided-interface=IF_KL_SL_Soll_hr
      SP_IF_KL_SMod_SIH_Stufe_LED_hl_XIX_Grundumfang_XIX_Klima: provided-interface=IF_KL_SMod_SIH_Stufe_LED_hl
      SP_IF_KL_SMod_SIH_Stufe_LED_hr_XIX_Grundumfang_XIX_Klima: provided-interface=IF_KL_SMod_SIH_Stufe_LED_hr
      SP_IF_KL_SMod_SIL_Stufe_LED_hl_XIX_Grundumfang_XIX_Klima: provided-interface=IF_KL_SMod_SIL_Stufe_LED_hl
      SP_IF_KL_SMod_SIL_Stufe_LED_hr_XIX_Grundumfang_XIX_Klima: provided-interface=IF_KL_SMod_SIL_Stufe_LED_hr
      SP_IF_KL_SoSe_Intensitaet_BFS_XIX_Grundumfang_XIX_Klima: provided-interface=IF_KL_SoSe_Intensitaet_BFS
      SP_IF_KL_SoSe_Intensitaet_FS_XIX_Grundumfang_XIX_Klima: provided-interface=IF_KL_SoSe_Intensitaet_FS
      SP_IF_KL_Spannungs_Anf_XIX_Grundumfang_XIX_Klima: provided-interface=IF_KL_Spannungs_Anf
      SP_IF_KL_Standklima_RemoteModus_XIX_Grundumfang_XIX_Klima: provided-interface=IF_KL_Standklima_RemoteModus
      SP_IF_KL_Standklima_Status_02_XIX_Grundumfang_XIX_Klima: provided-interface=IF_KL_Standklima_Status_02
      SP_IF_KL_Standklima_Status_03_XIX_Grundumfang_XIX_Klima: provided-interface=IF_KL_Standklima_Status_03
      SP_IF_KL_StartStopp_Info_XIX_Grundumfang_XIX_Klima: provided-interface=IF_KL_StartStopp_Info
      SP_IF_KL_Status_Battkuehlung_XIX_Grundumfang_XIX_Klima: provided-interface=IF_KL_Status_Battkuehlung
      SP_IF_KL_Status_EoHVL_EKK_XIX_Grundumfang_XIX_Klima: provided-interface=IF_KL_Status_EoHVL_EKK
      SP_IF_KL_Status_EoHVL_Heizer_2_XIX_Grundumfang_XIX_Klima: provided-interface=IF_KL_Status_EoHVL_Heizer_2
      SP_IF_KL_Status_EoHVL_Heizer_3_XIX_Grundumfang_XIX_Klima: provided-interface=IF_KL_Status_EoHVL_Heizer_3
      SP_IF_KL_Status_EoHVL_Heizer_XIX_Grundumfang_XIX_Klima: provided-interface=IF_KL_Status_EoHVL_Heizer
      SP_IF_KL_Status_Soll_XIX_Grundumfang_XIX_Klima: provided-interface=IF_KL_Status_Soll
      SP_IF_KL_StellgliedtestINV_Heck_XIX_Grundumfang_XIX_Klima: provided-interface=IF_KL_StellgliedtestINV_Heck
      SP_IF_KL_STH_aktiv_XIX_Grundumfang_XIX_Klima: provided-interface=IF_KL_STH_aktiv
      SP_IF_KL_STH_Ansteuerung_XIX_Grundumfang_XIX_Klima: provided-interface=IF_KL_STH_Ansteuerung
      SP_IF_KL_STH_Betriebsdauer_lang_XIX_Grundumfang_XIX_Klima: provided-interface=IF_KL_STH_Betriebsdauer_lang
      SP_IF_KL_STH_Betriebsdauer_XIX_Grundumfang_XIX_Klima: provided-interface=IF_KL_STH_Betriebsdauer
      SP_IF_KL_STL_aktiv_XIX_Grundumfang_XIX_Klima: provided-interface=IF_KL_STL_aktiv
      SP_IF_KL_Stopp_Wiederstart_Anz_{01..09}_XIX_Grundumfang_XIX_Klima: provided-interface=IF_KL_Stopp_Wiederstart_Anz_{01..09}
      SP_IF_KL_Stopp_Wiederstart_Anz_Std1_XIX_Grundumfang_XIX_Klima: provided-interface=IF_KL_Stopp_Wiederstart_Anz_Std1
      SP_IF_KL_Stopp_Wiederstart_Anz_Std2_XIX_Grundumfang_XIX_Klima: provided-interface=IF_KL_Stopp_Wiederstart_Anz_Std2
      SP_IF_KL_T_Charge_XIX_Grundumfang_XIX_Klima: provided-interface=IF_KL_T_Charge
      SP_IF_KL_Temp_HL_Soll_XIX_Grundumfang_XIX_Klima: provided-interface=IF_KL_Temp_HL_Soll
      SP_IF_KL_Temp_Kundenwunsch_XIX_Grundumfang_XIX_Klima: provided-interface=IF_KL_Temp_Kundenwunsch
      SP_IF_KL_Temp_vor_NTK_XIX_Grundumfang_XIX_Klima: provided-interface=IF_KL_Temp_vor_NTK
      SP_IF_KL_Temp_ZH_Soll_XIX_Grundumfang_XIX_Klima: provided-interface=IF_KL_Temp_ZH_Soll
      SP_IF_KL_Thermomanagement_XIX_Grundumfang_XIX_Klima: provided-interface=IF_KL_Thermomanagement
      SP_IF_KL_UIF_Parametersatz_XIX_Grundumfang_XIX_Klima: provided-interface=IF_KL_UIF_Parametersatz
      SP_IF_KL_Umluft_Taste_XIX_Grundumfang_XIX_Klima: provided-interface=IF_KL_Umluft_Taste
      SP_IF_KL_Umluftklappe_Status_XIX_Grundumfang_XIX_Klima: provided-interface=IF_KL_Umluftklappe_Status
      SP_IF_KL_Variante_Standheizung_XIX_Grundumfang_XIX_Klima: provided-interface=IF_KL_Variante_Standheizung
      SP_IF_KL_Ventil_03_Soll_XIX_Grundumfang_XIX_Klima: provided-interface=IF_KL_Ventil_03_Soll
      SP_IF_KL_Verdeckstatus_XIX_Grundumfang_XIX_Klima: provided-interface=IF_KL_Verdeckstatus
      SP_IF_KL_VK_Anf_XIX_Grundumfang_XIX_Klima: provided-interface=IF_KL_VK_Anf
      SP_IF_KL_VK_Betriebsdauer_XIX_Grundumfang_XIX_Klima: provided-interface=IF_KL_VK_Betriebsdauer
      SP_IF_KL_VoKo_LED_XIX_Grundumfang_XIX_Klima: provided-interface=IF_KL_VoKo_LED
      SP_IF_KL_Voko_Status_XIX_Grundumfang_XIX_Klima: provided-interface=IF_KL_Voko_Status
      SP_IF_KL_Vorkond_Strategie_XIX_Grundumfang_XIX_Klima: provided-interface=IF_KL_Vorkond_Strategie
      SP_IF_KL_Vorwarn_HVHeizer_Leistung_XIX_Grundumfang_XIX_Klima: provided-interface=IF_KL_Vorwarn_HVHeizer_Leistung
      SP_IF_KL_Vorwarn_Komp_ein_XIX_Grundumfang_XIX_Klima: provided-interface=IF_KL_Vorwarn_Komp_ein
      SP_IF_KL_Vorwarn_Zuheizer_ein_XIX_Grundumfang_XIX_Klima: provided-interface=IF_KL_Vorwarn_Zuheizer_ein
      SP_IF_KL_WaPu_XIX_Grundumfang_XIX_Klima: provided-interface=IF_KL_WaPu
      SP_IF_KL_Wasserheizer_Ansteuerung_XIX_Grundumfang_XIX_Klima: provided-interface=IF_KL_Wasserheizer_Ansteuerung
      SP_IF_KL_Wasserheizer_IstTemp_Ausgang_XIX_Grundumfang_XIX_Klima: provided-interface=IF_KL_Wasserheizer_IstTemp_Ausgang
      SP_IF_KL_Wasserheizer_IstTemp_Eingang_XIX_Grundumfang_XIX_Klima: provided-interface=IF_KL_Wasserheizer_IstTemp_Eingang
      SP_IF_KL_Wasserheizer_SollTemp_Ausgang_XIX_Grundumfang_XIX_Klima: provided-interface=IF_KL_Wasserheizer_SollTemp_Ausgang
      SP_IF_KL_Wasserheizer_Status_XIX_Grundumfang_XIX_Klima: provided-interface=IF_KL_Wasserheizer_Status
      SP_IF_KL_ZR_Anforderung_XIX_Grundumfang_XIX_Klima: provided-interface=IF_KL_ZR_Anforderung
      SP_IF_KL_Zuheizer_Freigabe_XIX_Grundumfang_XIX_Klima: provided-interface=IF_KL_Zuheizer_Freigabe
      SP_IF_KL_Zustand_XIX_Grundumfang_XIX_Klima: provided-interface=IF_KL_Zustand
      SP_IF_KL_ZZ_Betriebsmodus_XIX_Grundumfang_XIX_Klima: provided-interface=IF_KL_ZZ_Betriebsmodus
      SP_IF_KL_ZZ_Minute_XIX_Grundumfang_XIX_Klima: provided-interface=IF_KL_ZZ_Minute
      SP_IF_KL_ZZ_Monat_XIX_Grundumfang_XIX_Klima: provided-interface=IF_KL_ZZ_Monat
      SP_IF_KL_ZZ_Status_Timer_XIX_Grundumfang_XIX_Klima: provided-interface=IF_KL_ZZ_Status_Timer
      SP_IF_KL_ZZ_Stunde_XIX_Grundumfang_XIX_Klima: provided-interface=IF_KL_ZZ_Stunde
      SP_IF_KL_ZZ_Tag_XIX_Grundumfang_XIX_Klima: provided-interface=IF_KL_ZZ_Tag
      SP_IF_Klemme_15_XIX_Grundumfang_XIX_Klima: provided-interface=IF_Klemme_15
      SP_IF_KLhs_02_alt_XIX_Grundumfang_XIX_Klima: provided-interface=IF_KLhs_02_alt
      SP_IF_Klima_Abschaltstufe_XIX_Grundumfang_XIX_Klima: provided-interface=IF_Klima_Abschaltstufe
      SP_IF_Klima_Nachlauftyp_XIX_Grundumfang_XIX_Klima: provided-interface=IF_Klima_Nachlauftyp
      SP_IF_Klima_Transport_Mode_XIX_Grundumfang_XIX_Klima: provided-interface=IF_Klima_Transport_Mode
      SP_IF_KN_KL_DiagPfad_XIX_Grundumfang_XIX_Klima: provided-interface=IF_KN_KL_DiagPfad
      SP_IF_KompressorModus_XIX_Grundumfang_XIX_Klima: provided-interface=IF_KompressorModus
      SP_IF_KPVe_Auto_Toggle_XIX_Grundumfang_XIX_Klima: provided-interface=IF_KPVe_Auto_Toggle
      SP_IF_KPVe_Einheit_XIX_Grundumfang_XIX_Klima: provided-interface=IF_KPVe_Einheit
      SP_IF_KPVe_Funktion_AC_max_XIX_Grundumfang_XIX_Klima: provided-interface=IF_KPVe_Funktion_AC_max
      SP_IF_KPVe_Funktion_AC_XIX_Grundumfang_XIX_Klima: provided-interface=IF_KPVe_Funktion_AC
      SP_IF_KPVe_Funktion_Auto_li_XIX_Grundumfang_XIX_Klima: provided-interface=IF_KPVe_Funktion_Auto_li
      SP_IF_KPVe_Funktion_AutoSiKli_li_XIX_Grundumfang_XIX_Klima: provided-interface=IF_KPVe_Funktion_AutoSiKli_li
      SP_IF_KPVe_Funktion_AutoSiKli_re_XIX_Grundumfang_XIX_Klima: provided-interface=IF_KPVe_Funktion_AutoSiKli_re
      SP_IF_KPVe_Funktion_AutoUmluft_XIX_Grundumfang_XIX_Klima: provided-interface=IF_KPVe_Funktion_AutoUmluft
      SP_IF_KPVe_Funktion_Beduftung_XIX_Grundumfang_XIX_Klima: provided-interface=IF_KPVe_Funktion_Beduftung
      SP_IF_KPVe_Funktion_Defrost_XIX_Grundumfang_XIX_Klima: provided-interface=IF_KPVe_Funktion_Defrost
      SP_IF_KPVe_Funktion_ECO_XIX_Grundumfang_XIX_Klima: provided-interface=IF_KPVe_Funktion_ECO
      SP_IF_KPVe_Funktion_ECO_Zone_XIX_Grundumfang_XIX_Klima: provided-interface=IF_KPVe_Funktion_ECO_Zone
      SP_IF_KPVe_Funktion_FSH_XIX_Grundumfang_XIX_Klima: provided-interface=IF_KPVe_Funktion_FSH
      SP_IF_KPVe_Funktion_HSH_XIX_Grundumfang_XIX_Klima: provided-interface=IF_KPVe_Funktion_HSH
      SP_IF_KPVe_Funktion_Ionisator_XIX_Grundumfang_XIX_Klima: provided-interface=IF_KPVe_Funktion_Ionisator
      SP_IF_KPVe_Funktion_Joker_Taste_XIX_Grundumfang_XIX_Klima: provided-interface=IF_KPVe_Funktion_Joker_Taste
      SP_IF_KPVe_Funktion_Klima_Menue_MMI_XIX_Grundumfang_XIX_Klima: provided-interface=IF_KPVe_Funktion_Klima_Menue_MMI
      SP_IF_KPVe_Funktion_Konditionierung_XIX_Grundumfang_XIX_Klima: provided-interface=IF_KPVe_Funktion_Konditionierung
      SP_IF_KPVe_Funktion_Locked_XIX_Grundumfang_XIX_Klima: provided-interface=IF_KPVe_Funktion_Locked
      SP_IF_KPVe_Funktion_OBD_XIX_Grundumfang_XIX_Klima: provided-interface=IF_KPVe_Funktion_OBD
      SP_IF_KPVe_Funktion_Off_XIX_Grundumfang_XIX_Klima: provided-interface=IF_KPVe_Funktion_Off
      SP_IF_KPVe_Funktion_PureAir_XIX_Grundumfang_XIX_Klima: provided-interface=IF_KPVe_Funktion_PureAir
      SP_IF_KPVe_Funktion_Rear_XIX_Grundumfang_XIX_Klima: provided-interface=IF_KPVe_Funktion_Rear
      SP_IF_KPVe_Funktion_Restwaerme_XIX_Grundumfang_XIX_Klima: provided-interface=IF_KPVe_Funktion_Restwaerme
      SP_IF_KPVe_Funktion_Sync_XIX_Grundumfang_XIX_Klima: provided-interface=IF_KPVe_Funktion_Sync
      SP_IF_KPVe_Funktion_Umluft_XIX_Grundumfang_XIX_Klima: provided-interface=IF_KPVe_Funktion_Umluft
      SP_IF_KPVe_Funktionsbeleuchtung_XIX_Grundumfang_XIX_Klima: provided-interface=IF_KPVe_Funktionsbeleuchtung
      SP_IF_KPVe_Geblaese_Auto_li_XIX_Grundumfang_XIX_Klima: provided-interface=IF_KPVe_Geblaese_Auto_li
      SP_IF_KPVe_Geblaese_Begrenzung_XIX_Grundumfang_XIX_Klima: provided-interface=IF_KPVe_Geblaese_Begrenzung
      SP_IF_KPVe_Geblaese_Stufe_li_XIX_Grundumfang_XIX_Klima: provided-interface=IF_KPVe_Geblaese_Stufe_li
      SP_IF_KPVe_Kopfraumheizung_li_XIX_Grundumfang_XIX_Klima: provided-interface=IF_KPVe_Kopfraumheizung_li
      SP_IF_KPVe_Kopfraumheizung_re_XIX_Grundumfang_XIX_Klima: provided-interface=IF_KPVe_Kopfraumheizung_re
      SP_IF_KPVe_LCD_XIX_Grundumfang_XIX_Klima: provided-interface=IF_KPVe_LCD
      SP_IF_KPVe_Lenker_Position_XIX_Grundumfang_XIX_Klima: provided-interface=IF_KPVe_Lenker_Position
      SP_IF_KPVe_Luftverteilung_Auto_li_XIX_Grundumfang_XIX_Klima: provided-interface=IF_KPVe_Luftverteilung_Auto_li
      SP_IF_KPVe_Luftverteilung_Mitte_li_XIX_Grundumfang_XIX_Klima: provided-interface=IF_KPVe_Luftverteilung_Mitte_li
      SP_IF_KPVe_Luftverteilung_Oben_li_XIX_Grundumfang_XIX_Klima: provided-interface=IF_KPVe_Luftverteilung_Oben_li
      SP_IF_KPVe_Luftverteilung_Unten_li_XIX_Grundumfang_XIX_Klima: provided-interface=IF_KPVe_Luftverteilung_Unten_li
      SP_IF_KPVe_OBD_Gruppe_XIX_Grundumfang_XIX_Klima: provided-interface=IF_KPVe_OBD_Gruppe
      SP_IF_KPVe_Sitzheizung_li_XIX_Grundumfang_XIX_Klima: provided-interface=IF_KPVe_Sitzheizung_li
      SP_IF_KPVe_Sitzheizung_re_XIX_Grundumfang_XIX_Klima: provided-interface=IF_KPVe_Sitzheizung_re
      SP_IF_KPVe_Sitzlueftung_li_XIX_Grundumfang_XIX_Klima: provided-interface=IF_KPVe_Sitzlueftung_li
      SP_IF_KPVe_Sitzlueftung_re_XIX_Grundumfang_XIX_Klima: provided-interface=IF_KPVe_Sitzlueftung_re
      SP_IF_KPVe_Suchbeleuchtung_XIX_Grundumfang_XIX_Klima: provided-interface=IF_KPVe_Suchbeleuchtung
      SP_IF_KPVe_Symbol_Luftmenge_li_XIX_Grundumfang_XIX_Klima: provided-interface=IF_KPVe_Symbol_Luftmenge_li
      SP_IF_KPVe_Symbol_Luftverteilung_li_XIX_Grundumfang_XIX_Klima: provided-interface=IF_KPVe_Symbol_Luftverteilung_li
      SP_IF_KPVe_Temp_li_XIX_Grundumfang_XIX_Klima: provided-interface=IF_KPVe_Temp_li
      SP_IF_KPVe_Temp_re_XIX_Grundumfang_XIX_Klima: provided-interface=IF_KPVe_Temp_re
      SP_IF_KPVe_Verbau_AutoSikli_XIX_Grundumfang_XIX_Klima: provided-interface=IF_KPVe_Verbau_AutoSikli
      SP_IF_KRH_Soll_li_XIX_Grundumfang_XIX_Klima: provided-interface=IF_KRH_Soll_li
      SP_IF_KRH_Soll_re_XIX_Grundumfang_XIX_Klima: provided-interface=IF_KRH_Soll_re
      SP_IF_LHRe_01_AnsteuerVorgabe_A_XIX_Grundumfang_XIX_Klima: provided-interface=IF_LHRe_01_AnsteuerVorgabe_A
      SP_IF_LHRe_01_AnsteuerVorgabe_B_XIX_Grundumfang_XIX_Klima: provided-interface=IF_LHRe_01_AnsteuerVorgabe_B
      SP_IF_LHRe_01_Config_NTC_A_XIX_Grundumfang_XIX_Klima: provided-interface=IF_LHRe_01_Config_NTC_A
      SP_IF_LHRe_01_Config_NTC_B_XIX_Grundumfang_XIX_Klima: provided-interface=IF_LHRe_01_Config_NTC_B
      SP_IF_LHRe_Global_Unterbrechen_Inv_XIX_Grundumfang_XIX_Klima: provided-interface=IF_LHRe_Global_Unterbrechen_Inv
      SP_IF_Luftmenge_Innenraum_PMS_XIX_Grundumfang_XIX_Klima: provided-interface=IF_Luftmenge_Innenraum_PMS
      SP_IF_MD1_Position_4Bit_XIX_Grundumfang_XIX_Klima: provided-interface=IF_MD1_Position_4Bit
      SP_IF_Messung_Enable_PMS_XIX_Grundumfang_XIX_Klima: provided-interface=IF_Messung_Enable_PMS
      SP_IF_MO_FSA_Sensorheizung_XIX_Grundumfang_XIX_Klima: provided-interface=IF_MO_FSA_Sensorheizung
      SP_IF_MRollo_Position_4Bit_XIX_Grundumfang_XIX_Klima: provided-interface=IF_MRollo_Position_4Bit
      SP_IF_Navigationsattribute_XIX_Grundumfang_XIX_Klima: provided-interface=IF_Navigationsattribute
      SP_IF_NM_Klima_CBV_AWB_XIX_Grundumfang_XIX_Klima: provided-interface=IF_NM_Klima_CBV_AWB
      SP_IF_NM_Klima_CBV_CRI_XIX_Grundumfang_XIX_Klima: provided-interface=IF_NM_Klima_CBV_CRI
      SP_IF_NM_Klima_NM_aktiv_Diagnose_XIX_Grundumfang_XIX_Klima: provided-interface=IF_NM_Klima_NM_aktiv_Diagnose
      SP_IF_NM_Klima_NM_aktiv_KL15_XIX_Grundumfang_XIX_Klima: provided-interface=IF_NM_Klima_NM_aktiv_KL15
      SP_IF_NM_Klima_NM_aktiv_Tmin_XIX_Grundumfang_XIX_Klima: provided-interface=IF_NM_Klima_NM_aktiv_Tmin
      SP_IF_NM_Klima_NM_State_XIX_Grundumfang_XIX_Klima: provided-interface=IF_NM_Klima_NM_State
      SP_IF_NM_Klima_UDS_CC_XIX_Grundumfang_XIX_Klima: provided-interface=IF_NM_Klima_UDS_CC
      SP_IF_NM_Klima_Wakeup_XIX_Grundumfang_XIX_Klima: provided-interface=IF_NM_Klima_Wakeup
      SP_IF_OBDProtocol_Klima_XIX_Grundumfang_XIX_Klima: provided-interface=IF_OBDProtocol_Klima
      SP_IF_PCU_Aussentemp_gef_XIX_Grundumfang_XIX_Klima: provided-interface=IF_PCU_Aussentemp_gef
      SP_IF_PCU_Ein_XIX_Grundumfang_XIX_Klima: provided-interface=IF_PCU_Ein
      SP_IF_PCU_FS_Luftfeuchte_rel_XIX_Grundumfang_XIX_Klima: provided-interface=IF_PCU_FS_Luftfeuchte_rel
      SP_IF_PCU_FSA_Luftfeuchte_rel_XIX_Grundumfang_XIX_Klima: provided-interface=IF_PCU_FSA_Luftfeuchte_rel
      SP_IF_PCU_Funktionstest_XIX_Grundumfang_XIX_Klima: provided-interface=IF_PCU_Funktionstest
      SP_IF_PCU_Geblaese_Status_XIX_Grundumfang_XIX_Klima: provided-interface=IF_PCU_Geblaese_Status
      SP_IF_PCU_Innen_Temp_XIX_Grundumfang_XIX_Klima: provided-interface=IF_PCU_Innen_Temp
      SP_IF_PCU_Kennlinie_XIX_Grundumfang_XIX_Klima: provided-interface=IF_PCU_Kennlinie
      SP_IF_PCU_Umluftklappe_Status_XIX_Grundumfang_XIX_Klima: provided-interface=IF_PCU_Umluftklappe_Status
      SP_IF_PTC_Aktiv_XIX_Grundumfang_XIX_Klima: provided-interface=IF_PTC_Aktiv
      SP_IF_PTC_Fehlerstatus_XIX_Grundumfang_XIX_Klima: provided-interface=IF_PTC_Fehlerstatus
      SP_IF_PTC_I_ist_XIX_Grundumfang_XIX_Klima: provided-interface=IF_PTC_I_ist
      SP_IF_PTC_Nenn_Strom_XIX_Grundumfang_XIX_Klima: provided-interface=IF_PTC_Nenn_Strom
      SP_IF_PTC_P_ist_XIX_Grundumfang_XIX_Klima: provided-interface=IF_PTC_P_ist
      SP_IF_PTCs_01_alt_XIX_Grundumfang_XIX_Klima: provided-interface=IF_PTCs_01_alt
      SP_IF_Scheibenreinigung_XIX_Grundumfang_XIX_Klima: provided-interface=IF_Scheibenreinigung
      SP_IF_SI_T_Mode_XIX_Grundumfang_XIX_Klima: provided-interface=IF_SI_T_Mode
      SP_IF_SI_T_Schutz_XIX_Grundumfang_XIX_Klima: provided-interface=IF_SI_T_Schutz
      SP_IF_SIL_Stufe_LED_HL_XIX_Grundumfang_XIX_Klima: provided-interface=IF_SIL_Stufe_LED_HL
      SP_IF_SIL_Stufe_LED_HR_XIX_Grundumfang_XIX_Klima: provided-interface=IF_SIL_Stufe_LED_HR
      SP_IF_SOK_FoD_Klima_Req_Challenge_XIX_Grundumfang_XIX_Klima: provided-interface=IF_SOK_FoD_Klima_Req_Challenge
      SP_IF_Soll_Lehne_LLR_li_1_XIX_Grundumfang_XIX_Klima: provided-interface=IF_Soll_Lehne_LLR_li_1
      SP_IF_Soll_Lehne_LLR_li_2_XIX_Grundumfang_XIX_Klima: provided-interface=IF_Soll_Lehne_LLR_li_2
      SP_IF_Soll_Lehne_LLR_re_1_XIX_Grundumfang_XIX_Klima: provided-interface=IF_Soll_Lehne_LLR_re_1
      SP_IF_Soll_Lehne_LLR_re_2_XIX_Grundumfang_XIX_Klima: provided-interface=IF_Soll_Lehne_LLR_re_2
      SP_IF_Soll_Sitz_LLR_li_1_XIX_Grundumfang_XIX_Klima: provided-interface=IF_Soll_Sitz_LLR_li_1
      SP_IF_Soll_Sitz_LLR_li_2_XIX_Grundumfang_XIX_Klima: provided-interface=IF_Soll_Sitz_LLR_li_2
      SP_IF_Soll_Sitz_LLR_re_1_XIX_Grundumfang_XIX_Klima: provided-interface=IF_Soll_Sitz_LLR_re_1
      SP_IF_Soll_Sitz_LLR_re_2_XIX_Grundumfang_XIX_Klima: provided-interface=IF_Soll_Sitz_LLR_re_2
      SP_IF_STRG1_Adresse_Aktuator_XIX_Grundumfang_XIX_Klima: provided-interface=IF_STRG1_Adresse_Aktuator
      SP_IF_STRG1_Geschwindigkeitsvorgabe_XIX_Grundumfang_XIX_Klima: provided-interface=IF_STRG1_Geschwindigkeitsvorgabe
      SP_IF_STRG1_Notlauffreigabe_XIX_Grundumfang_XIX_Klima: provided-interface=IF_STRG1_Notlauffreigabe
      SP_IF_STRG1_Select_Positionsvorgabe_XIX_Grundumfang_XIX_Klima: provided-interface=IF_STRG1_Select_Positionsvorgabe
      SP_IF_STRG1_Soll_Position_Aktuator_XIX_Grundumfang_XIX_Klima: provided-interface=IF_STRG1_Soll_Position_Aktuator
      SP_IF_STRG1_Spulenbestromung_XIX_Grundumfang_XIX_Klima: provided-interface=IF_STRG1_Spulenbestromung
      SP_IF_STRG4_Adresse_Aktuator_XIX_Grundumfang_XIX_Klima: provided-interface=IF_STRG4_Adresse_Aktuator
      SP_IF_STRG4_Clear_Event_Flags_XIX_Grundumfang_XIX_Klima: provided-interface=IF_STRG4_Clear_Event_Flags
      SP_IF_STRG4_Drehrichtung_XIX_Grundumfang_XIX_Klima: provided-interface=IF_STRG4_Drehrichtung
      SP_IF_STRG4_Freigabe_Blockiererkennung_XIX_Grundumfang_XIX_Klima: provided-interface=IF_STRG4_Freigabe_Blockiererkennung
      SP_IF_STRG4_Geschwindigkeitsvorgabe_XIX_Grundumfang_XIX_Klima: provided-interface=IF_STRG4_Geschwindigkeitsvorgabe
      SP_IF_STRG4_Notlauffreigabe_XIX_Grundumfang_XIX_Klima: provided-interface=IF_STRG4_Notlauffreigabe
      SP_IF_STRG4_Notlaufposition_XIX_Grundumfang_XIX_Klima: provided-interface=IF_STRG4_Notlaufposition
      SP_IF_STRG4_Programmierdaten_speichern_XIX_Grundumfang_XIX_Klima: provided-interface=IF_STRG4_Programmierdaten_speichern
      SP_IF_STRG4_Select_Positionsvorgabe_XIX_Grundumfang_XIX_Klima: provided-interface=IF_STRG4_Select_Positionsvorgabe
      SP_IF_STRG4_Soll_Position_Aktuator_XIX_Grundumfang_XIX_Klima: provided-interface=IF_STRG4_Soll_Position_Aktuator
      SP_IF_STRG4_Spulenbestromung_XIX_Grundumfang_XIX_Klima: provided-interface=IF_STRG4_Spulenbestromung
      SP_IF_STRG4_Start_Position_Aktuator_XIX_Grundumfang_XIX_Klima: provided-interface=IF_STRG4_Start_Position_Aktuator
      SP_IF_STRG4_Stopmodus_XIX_Grundumfang_XIX_Klima: provided-interface=IF_STRG4_Stopmodus
      SP_IF_Thermo_Pred_Innen_Kunde_Anf_XIX_Grundumfang_XIX_Klima: provided-interface=IF_Thermo_Pred_Innen_Kunde_Anf
      SP_IF_Thermo_Pred_Innen_System_Anf_XIX_Grundumfang_XIX_Klima: provided-interface=IF_Thermo_Pred_Innen_System_Anf
      SP_IF_Thermo_Pred_P_dyn_In_Efficien1_XIX_Grundumfang_XIX_Klima: provided-interface=IF_Thermo_Pred_P_dyn_In_Efficien1
      SP_IF_Thermo_Pred_P_dyn_In_Efficien2_XIX_Grundumfang_XIX_Klima: provided-interface=IF_Thermo_Pred_P_dyn_In_Efficien2
      SP_IF_Thermo_Pred_P_dyn_In_Standard_XIX_Grundumfang_XIX_Klima: provided-interface=IF_Thermo_Pred_P_dyn_In_Standard
      SP_IF_Thermo_Pred_P_dyn_Innen_XIX_Grundumfang_XIX_Klima: provided-interface=IF_Thermo_Pred_P_dyn_Innen
      SP_IF_Thermo_Pred_P_stat_In_Efficien1_XIX_Grundumfang_XIX_Klima: provided-interface=IF_Thermo_Pred_P_stat_In_Efficien1
      SP_IF_Thermo_Pred_P_stat_In_Efficien2_XIX_Grundumfang_XIX_Klima: provided-interface=IF_Thermo_Pred_P_stat_In_Efficien2
      SP_IF_Thermo_Pred_P_stat_In_Standard_XIX_Grundumfang_XIX_Klima: provided-interface=IF_Thermo_Pred_P_stat_In_Standard
      SP_IF_Thermo_Pred_P_stat_Innen_XIX_Grundumfang_XIX_Klima: provided-interface=IF_Thermo_Pred_P_stat_Innen
      SP_IF_Thermo_Pred_T_dyn_In_Efficien1_XIX_Grundumfang_XIX_Klima: provided-interface=IF_Thermo_Pred_T_dyn_In_Efficien1
      SP_IF_Thermo_Pred_T_dyn_In_Efficien2_XIX_Grundumfang_XIX_Klima: provided-interface=IF_Thermo_Pred_T_dyn_In_Efficien2
      SP_IF_Thermo_Pred_T_dyn_In_Standard_XIX_Grundumfang_XIX_Klima: provided-interface=IF_Thermo_Pred_T_dyn_In_Standard
      SP_IF_Thermo_Pred_T_dyn_Innen_XIX_Grundumfang_XIX_Klima: provided-interface=IF_Thermo_Pred_T_dyn_Innen
      SP_IF_Thermo_Verbrauch_BTL_Ueberlauf_XIX_Grundumfang_XIX_Klima: provided-interface=IF_Thermo_Verbrauch_BTL_Ueberlauf
      SP_IF_Thermo_Verbrauch_BTL_XIX_Grundumfang_XIX_Klima: provided-interface=IF_Thermo_Verbrauch_BTL
      SP_IF_Thermo_Verbrauch_Innen_Ueberlauf_XIX_Grundumfang_XIX_Klima: provided-interface=IF_Thermo_Verbrauch_Innen_Ueberlauf
      SP_IF_Thermo_Verbrauch_Innen_XIX_Grundumfang_XIX_Klima: provided-interface=IF_Thermo_Verbrauch_Innen
      SP_IF_UH_Jahr_XIX_Grundumfang_XIX_Klima: provided-interface=IF_UH_Jahr
      SP_IF_UH_Monat_XIX_Grundumfang_XIX_Klima: provided-interface=IF_UH_Monat
      SP_IF_UH_Tag_XIX_Grundumfang_XIX_Klima: provided-interface=IF_UH_Tag
      SP_IF_Umluft_XIX_Grundumfang_XIX_Klima: provided-interface=IF_Umluft
      SP_IF_Verbauposition_LLR_li_XIX_Grundumfang_XIX_Klima: provided-interface=IF_Verbauposition_LLR_li
      SP_IF_Verbauposition_LLR_re_XIX_Grundumfang_XIX_Klima: provided-interface=IF_Verbauposition_LLR_re
      SP_IF_ZAS_Kl_15_XIX_Grundumfang_XIX_Klima: provided-interface=IF_ZAS_Kl_15
      SP_IF_ZAS_Kl_S_XIX_Grundumfang_XIX_Klima: provided-interface=IF_ZAS_Kl_S
